VERSION ""

NS_ :

BS_:

BU_: TEST_NODE Pedalbox HUB_FL TORQUE_VECTOR TESTER Precharge DAQ Precharge

BO_ 2483028044 test_msg: 2 TEST_NODE
 SG_ test_sig : 0|16@1+ (1,0) [0|0] "" Vector__XXX

BO_ 2483028108 test_msg2: 2 TEST_NODE
 SG_ test_sig2 : 0|16@1+ (1,0) [0|0] "" Vector__XXX

BO_ 2483028172 test_msg3: 2 TEST_NODE
 SG_ test_sig3 : 0|16@1+ (1,0) [0|0] "" Vector__XXX

BO_ 2483028236 test_msg4: 2 TEST_NODE
 SG_ test_sig4 : 0|16@1+ (1,0) [0|0] "" Vector__XXX

BO_ 2483028300 test_msg5: 2 TEST_NODE
 SG_ test_sig5 : 0|16@1+ (1,0) [0|0] "" Vector__XXX

BO_ 2550136780 daq_response_TEST_NODE: 8 TEST_NODE
 SG_ daq_response : 0|64@1+ (1,0) [0|0] "" Vector__XXX

BO_ 2483028619 throttle_brake: 4 Pedalbox
 SG_ raw_brake : 16|16@1+ (1,0) [0|0] "" Vector__XXX
 SG_ raw_throttle : 0|16@1+ (1,0) [0|0] "" Vector__XXX

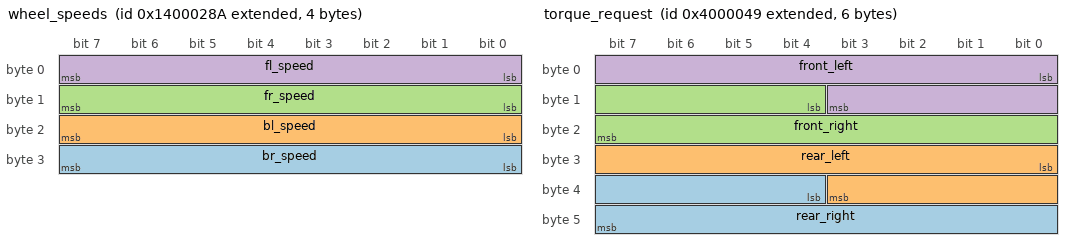
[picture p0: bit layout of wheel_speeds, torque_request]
BO_ 2483028618 wheel_speeds: 4 HUB_FL
 SG_ br_speed : 24|8@1+ (1,0) [0|0] "" Vector__XXX
 SG_ bl_speed : 16|8@1+ (1,0) [0|0] "" Vector__XXX
 SG_ fr_speed : 8|8@1+ (1,0) [0|0] "" Vector__XXX
 SG_ fl_speed : 0|8@1+ (1,0) [0|0] "" Vector__XXX

BO_ 2214592650 motor_current: 1 HUB_FL
 SG_ current : 0|8@1+ (1,0) [0|0] "" Vector__XXX

BO_ 2214592585 torque_request: 6 TORQUE_VECTOR
 SG_ rear_right : 36|12@1+ (1,0) [0|0] "" Vector__XXX
 SG_ rear_left : 24|12@1+ (1,0) [0|0] "" Vector__XXX
 SG_ front_right : 12|12@1+ (1,0) [0|0] "" Vector__XXX
 SG_ front_left : 0|12@1+ (1,0) [0|0] "" Vector__XXX

BO_ 2147490057 bitstream_flash_status: 1 TORQUE_VECTOR
 SG_ flash_timeout_rx : 1|1@1+ (1,0) [0|0] "" Vector__XXX
 SG_ flash_success : 0|1@1+ (1,0) [0|0] "" Vector__XXX

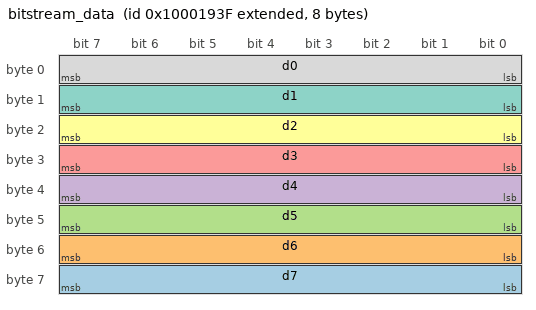
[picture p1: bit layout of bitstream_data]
BO_ 2415925567 bitstream_data: 8 TESTER
 SG_ d7 : 56|8@1+ (1,0) [0|0] "" Vector__XXX
 SG_ d6 : 48|8@1+ (1,0) [0|0] "" Vector__XXX
 SG_ d5 : 40|8@1+ (1,0) [0|0] "" Vector__XXX
 SG_ d4 : 32|8@1+ (1,0) [0|0] "" Vector__XXX
 SG_ d3 : 24|8@1+ (1,0) [0|0] "" Vector__XXX
 SG_ d2 : 16|8@1+ (1,0) [0|0] "" Vector__XXX
 SG_ d1 : 8|8@1+ (1,0) [0|0] "" Vector__XXX
 SG_ d0 : 0|8@1+ (1,0) [0|0] "" Vector__XXX

BO_ 2415925631 bitstream_request: 5 TESTER
 SG_ download_size : 1|32@1+ (1,0) [0|0] "" Vector__XXX
 SG_ download_request : 0|1@1+ (1,0) [0|0] "" Vector__XXX

BO_ 2281734202 test_precharge_msg: 1 Precharge
 SG_ test_precharge_sig : 0|8@1+ (1,0) [0|0] "" Vector__XXX

BO_ 2483028786 daq_command_TEST_NODE: 8 DAQ
 SG_ daq_command : 0|64@1+ (1,0) [0|0] "" Vector__XXX

BO_ 2214624554 test_bat_msg: 1 Precharge
 SG_ test_bat_sig : 0|8@1+ (1,0) [0|0] "" Vector__XXX

CM_ BO_ 2483028044 "test_msg desc";
CM_ BO_ 2483028108 "test_msg2 desc";
CM_ BO_ 2483028172 "test_msg2 desc";
CM_ BO_ 2483028236 "test_msg4 desc";
CM_ BO_ 2483028300 "test_msg5 desc";
CM_ BO_ 2550136780 "daq response from node TEST_NODE";
CM_ BO_ 2483028619 "throttle_brake desc";
CM_ BO_ 2483028618 "wheel_speeds desc";
CM_ BO_ 2214592650 "current of motor";
CM_ BO_ 2214592585 "Torque request for all motors.";
CM_ BO_ 2147490057 "Status message for bitstream flashing";
CM_ BO_ 2415925567 "Bitstream download command";
CM_ BO_ 2415925631 "Bitstream state command";
CM_ BO_ 2281734202 "test precharge desc";
CM_ BO_ 2483028786 "daq command for node TEST_NODE";
CM_ BO_ 2214624554 "test_bat_desc";
